AUTOSAR XML (schema 4-2-2)
# Copyright 2017 Mentor Graphics Corporation
# All rights reserved
# THIS WORK CONTAINS TRADE SECRET AND PROPRIETARY INFORMATION WHICH IS
# THE PROPERTY OF MENTOR GRAPHICS CORPORATION OR ITS LICENSORS AND IS
# SUBJECT TO LICENSE TERMS.
package /AUTOSAR/Services/Dcm
  swc implementation IMPL_Dcm: programming-language=C, sw-version=8.0.1, swc-bsw-mapping=SwcBswMapping_Dcm, vendor-id=31, behavior=IB_Dcm
    code-descriptors:
      code CODE_Dcm: artifact-descriptors=autosar-engineering-object={short-label=Dcm, category=SWSRC}
    resource consumption RC_Dcm
      memory section CODE: alignment=UNSPECIFIED, sw-addrmethod=CODE
  unit UnitNone
  5 x client server interface, all with is-service=true:
    CallbackDCMRequestServices
      operation StartProtocol: possible-error=[CallbackDCMRequestServices/E_OK, CallbackDCMRequestServices/E_NOT_OK, E_PROTOCOL_NOT_ALLOWED]
        arg ProtocolID: type=Dcm_ProtocolType, direction=IN
      operation StopProtocol: possible-error=[CallbackDCMRequestServices/E_OK, CallbackDCMRequestServices/E_NOT_OK]
        arg ProtocolID: type=Dcm_ProtocolType, direction=IN
      error E_OK: error-code=0
      error E_NOT_OK: error-code=1
      error E_PROTOCOL_NOT_ALLOWED: error-code=5
    ServiceRequestNotification
      operation Indication: possible-error=[ServiceRequestNotification/E_OK, ServiceRequestNotification/E_NOT_OK, E_REQUEST_NOT_ACCEPTED]
        6 x arg:
          SID: type=uint8, direction=IN
          RequestData: type=RequestDataArray, direction=IN
          DataSize: type=uint16, direction=IN
          ReqType: type=uint8, direction=IN
          SourceAddress: type=uint16, direction=IN
          ErrorCode: type=Dcm_NegativeResponseCodeType, direction=OUT
      operation Confirmation: possible-error=[ServiceRequestNotification/E_OK, ServiceRequestNotification/E_NOT_OK]
        4 x arg, all with direction=IN:
          SID: type=uint8
          ReqType: type=uint8
          SourceAddress: type=uint16
          ConfirmationStatus: type=Dcm_ConfirmationStatusType
      error E_OK: error-code=0
      error E_NOT_OK: error-code=1
      error E_REQUEST_NOT_ACCEPTED: error-code=8
    DCMServices
      4 x operation:
        GetActiveProtocol: possible-error=DCMServices/E_OK
          arg ActiveProtocol: type=Dcm_ProtocolType, direction=OUT
        GetSesCtrlType: possible-error=[DCMServices/E_OK, DCMServices/E_NOT_OK]
          arg SesCtrlType: type=Dcm_SesCtrlType, direction=OUT
        GetSecurityLevel: possible-error=[DCMServices/E_OK, DCMServices/E_NOT_OK]
          arg SecLevel: type=Dcm_SecLevelType, direction=OUT
        ResetToDefaultSession: possible-error=[DCMServices/E_OK, DCMServices/E_NOT_OK]
      error E_OK: error-code=0
      error E_NOT_OK: error-code=1
    ResponsePendingService
      operation GetResponsePendingStatus
        arg HasBeenSent: type=boolean, direction=OUT
    SecurityAccess_DcmDspSecurityRow
      operation GetSeed: possible-error=[SecurityAccess_DcmDspSecurityRow/E_OK, SecurityAccess_DcmDspSecurityRow/E_NOT_OK, DCM_E_PENDING]
        arg OpStatus: type=Dcm_OpStatusType, direction=IN
        arg Seed: type=SeedArrayType_DcmDspSecurityRow, direction=OUT
        arg ErrorCode: type=Dcm_NegativeResponseCodeType, direction=OUT
      operation CompareKey: possible-error=[SecurityAccess_DcmDspSecurityRow/E_OK, SecurityAccess_DcmDspSecurityRow/E_NOT_OK, DCM_E_PENDING, DCM_E_COMPARE_KEY_FAILED]
        arg Key: type=KeyArrayType_DcmDspSecurityRow, direction=IN
        arg OpStatus: type=Dcm_OpStatusType, direction=IN
        arg ErrorCode: type=Dcm_NegativeResponseCodeType, direction=OUT
      4 x error:
        E_OK: error-code=0
        E_NOT_OK: error-code=1
        DCM_E_PENDING: error-code=10
        DCM_E_COMPARE_KEY_FAILED: error-code=11
  5 x mode switch interface, all with is-service=true:
    DcmEcuReset
      mode group DcmEcuReset: type=DcmEcuReset
    DcmCommunicationControl
      mode group DcmCommunicationControl: type=DcmCommunicationControl
    DcmControlDTCSetting
      mode group DcmControlDTCSetting: type=DcmControlDTCSetting
    DcmModeRapidPowerShutDown
      mode group DcmModeRapidPowerShutDown: type=DcmModeRapidPowerShutDown
    DcmDiagnosticSessionControl
      mode group DcmDiagnosticSessionControl: type=DcmDiagnosticSessionControl
  impl type Dcm_ProtocolType: compu {0=DCM_OBD_ON_CAN, 1=DCM_OBD_ON_FLEXRAY, 2=DCM_OBD_ON_IP, 3=DCM_UDS_ON_CAN, 4=DCM_UDS_ON_FLEXRAY, 5=DCM_UDS_ON_IP, 6=DCM_ROE_ON_CAN, 7=DCM_ROE_ON_FLEXRAY, 8=DCM_ROE_ON_IP, 9=DCM_PERIODICTRANS_ON_CAN, 10=DCM_PERIODICTRANS_ON_FLEXRAY, 11=DCM_PERIODICTRANS_ON_IP, 12=DCM_NO_ACTIVE_PROTOCOL, 240..254=DCM_SUPPLIER_1..DCM_SUPPLIER_15}, implementation-data-type=uint8
  impl type Dcm_NegativeResponseCodeType: compu {16=DCM_E_GENERALREJECT, 17=DCM_E_SERVICENOTSUPPORTED, 18=DCM_E_SUBFUNCTIONNOTSUPPORTED, 19=DCM_E_INCORRECTMESSAGELENGTHORINVALIDFORMAT, 20=DCM_E_RESPONSETOOLONG, 33=DCM_E_BUSYREPEATREQUEST, 34=DCM_E_CONDITIONSNOTCORRECT, 36=DCM_E_REQUESTSEQUENCEERROR, 37=DCM_E_NORESPONSEFROMSUBNETCOMPONENT, 38=DCM_E_FAILUREPREVENTSEXECUTIONOFREQUESTEDACTION, 49=DCM_E_REQUESTOUTOFRANGE, 51=DCM_E_SECURITYACCESSDENIED, 53=DCM_E_INVALIDKEY, 54=DCM_E_EXCEEDNUMBEROFATTEMPTS, 55=DCM_E_REQUIREDTIMEDELAYNOTEXPIRED, 112=DCM_E_UPLOADDOWNLOADNOTACCEPTED, 113=DCM_E_TRANSFERDATASUSPENDED, 114=DCM_E_GENERALPROGRAMMINGFAILURE, 115=DCM_E_WRONGBLOCKSEQUENCECOUNTER, 126=DCM_E_SUBFUNCTIONNOTSUPPORTEDINACTIVESESSION, 127=DCM_E_SERVICENOTSUPPORTEDINACTIVESESSION, 129=DCM_E_RPMTOOHIGH, 130=DCM_E_RPMTOOLOW, 131=DCM_E_ENGINEISRUNNING, 132=DCM_E_ENGINEISNOTRUNNING, 133=DCM_E_ENGINERUNTIMETOOLOW, 134=DCM_E_TEMPERATURETOOHIGH, 135=DCM_E_TEMPERATURETOOLOW, 136=DCM_E_VEHICLESPEEDTOOHIGH, 137=DCM_E_VEHICLESPEEDTOOLOW, 138=DCM_E_THROTTLE_PEDALTOOHIGH, 139=DCM_E_THROTTLE_PEDALTOOLOW, 140=DCM_E_TRANSMISSIONRANGENOTINNEUTRAL, 141=DCM_E_TRANSMISSIONRANGENOTINGEAR, 143=DCM_E_BRAKESWITCH_NOTCLOSED, 144=DCM_E_SHIFTERLEVERNOTINPARK, 145=DCM_E_TORQUECONVERTERCLUTCHLOCKED, 146=DCM_E_VOLTAGETOOHIGH, 147=DCM_E_VOLTAGETOOLOW, 240..249=DCM_E_VMSCNC_0..DCM_E_VMSCNC_9, 250=DCM_E_VMSCNC_A, 251=DCM_E_VMSCNC_B, 252=DCM_E_VMSCNC_C, 253=DCM_E_VMSCNC_D, 254=DCM_E_VMSCNC_E}, implementation-data-type=uint8
  impl type Dcm_SecLevelType: compu {0=DCM_SEC_LEV_LOCKED, 1=DcmDspSecurityRow}, implementation-data-type=uint8
  impl type Dcm_SesCtrlType: compu {1=DCM_DEFAULT_SESSION, 2=DCM_PROGRAMMING_SESSION, 3=DCM_EXTENDED_DIAGNOSTIC_SESSION}, implementation-data-type=uint8
  impl type Dcm_OpStatusType: compu {0=DCM_INITIAL, 1=DCM_PENDING, 2=DCM_CANCEL, 3=DCM_FORCE_RCRRP_OK}, implementation-data-type=uint8
  impl type Dcm_ConfirmationStatusType: compu {0=DCM_RES_POS_OK, 1=DCM_RES_POS_NOT_OK, 2=DCM_RES_NEG_OK, 3=DCM_RES_NEG_NOT_OK}, implementation-data-type=uint8
  impl type Dcm_RoeStateType: compu {0=DCM_ROE_ACTIVE, 1=DCM_ROE_UNACTIVE}, implementation-data-type=uint8
  4 x impl type:
    KeyArrayType_DcmDspSecurityRow: category=ARRAY
      element ARRAYELEMENT: array-size=2, implementation-data-type=uint8
    RequestDataArray: category=ARRAY
      element ARRAYELEMENT: array-size=255, implementation-data-type=uint8
    SeedArrayType_DcmDspSecurityRow: category=ARRAY
      element ARRAYELEMENT: array-size=2, implementation-data-type=uint8
    Dcm_DidSupportedType: compu {0=DCM_DID_SUPPORTED, 1=DCM_DID_NOT_SUPPORTED}, implementation-data-type=uint8
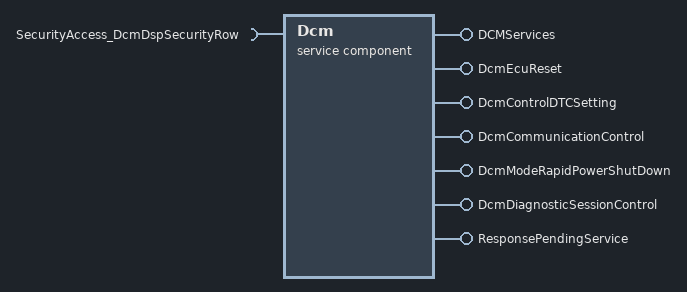
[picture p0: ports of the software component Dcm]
  service sw component type Dcm
    7 x provide port:
      DCMServices: provided-interface=DCMServices
        provided-com-specs:
          operation=GetActiveProtocol, queue-length=1
          operation=GetSesCtrlType, queue-length=1
          operation=GetSecurityLevel, queue-length=1
          operation=ResetToDefaultSession, queue-length=1
      DcmEcuReset: mode-switch-sender-com-spec{mode-group=DcmEcuReset, queue-length=2}, provided-interface=DcmEcuReset
      DcmControlDTCSetting: mode-switch-sender-com-spec{mode-group=DcmControlDTCSetting, queue-length=2}, provided-interface=DcmControlDTCSetting
      DcmCommunicationControl: mode-switch-sender-com-spec{mode-group=DcmCommunicationControl, queue-length=2}, provided-interface=DcmCommunicationControl
      DcmModeRapidPowerShutDown: mode-switch-sender-com-spec{mode-group=DcmModeRapidPowerShutDown, queue-length=2}, provided-interface=DcmModeRapidPowerShutDown
      DcmDiagnosticSessionControl: mode-switch-sender-com-spec{mode-group=DcmDiagnosticSessionControl, queue-length=2}, provided-interface=DcmDiagnosticSessionControl
      ResponsePendingService: server-com-spec{operation=GetResponsePendingStatus, queue-length=1}, provided-interface=ResponsePendingService
    require port SecurityAccess_DcmDspSecurityRow: required-interface=SecurityAccess_DcmDspSecurityRow
    behavior IB_Dcm: data-type-mapping=DcmModeMappingSet, handle-termination-and-restart=NO-SUPPORT, included-data-type-set=data-type=[Dcm_ProtocolType, Dcm_NegativeResponseCodeType, Dcm_SecLevelType, Dcm_SesCtrlType, Dcm_OpStatusType, Dcm_ConfirmationStatusType, Dcm_RoeStateType, Dcm_DidSupportedType]
      5 x operation invoked event:
        OI_GetActiveProtocol: start-on-event=RE_GetActiveProtocol, operation=DCMServices.GetActiveProtocol
        OI_GetSesCtrlType: start-on-event=RE_GetSesCtrlType, operation=DCMServices.GetSesCtrlType
        OI_GetSecurityLevel: start-on-event=RE_GetSecurityLevel, operation=DCMServices.GetSecurityLevel
        OI_ResetToDefaultSession: start-on-event=RE_ResetToDefaultSession, operation=DCMServices.ResetToDefaultSession
        OI_GetResponsePendingStatus: start-on-event=RE_GetResponsePendingStatus, operation=ResponsePendingService.GetResponsePendingStatus
      13 x runnable:
        RE_Dcm_ClearDiagnosticInformation: symbol=Dcm_SE_Dcm_ClearDiagnosticInformation
        RE_Dcm_DiagnosticSessionControl: symbol=Dcm_SE_Dcm_DiagnosticSessionControl
        RE_Dcm_MainFunction: symbol=Dcm_MainFunction
        RE_Dcm_ReadDTCInformation: symbol=Dcm_SE_Dcm_ReadDTCInformation
        RE_Dcm_ReadDataByIdentifier: symbol=Dcm_SE_Dcm_ReadDataByIdentifier
        RE_Dcm_SecurityAccess: symbol=Dcm_SE_Dcm_SecurityAccess
          sync call SSCP_SecurityAccess_DcmDspSecurityRow_CompareKey: operation=SecurityAccess_DcmDspSecurityRow.CompareKey, timeout=0.0
          sync call SSCP_SecurityAccess_DcmDspSecurityRow_GetSeed: operation=SecurityAccess_DcmDspSecurityRow.GetSeed, timeout=0.0
        RE_Dcm_TesterPresent: symbol=Dcm_SE_Dcm_TesterPresent
        RE_Dcm_WriteDataByIdentifier: symbol=Dcm_SE_Dcm_WriteDataByIdentifier
        RE_GetActiveProtocol: can-be-invoked-concurrently=true, symbol=Dcm_GetActiveProtocol
        RE_GetResponsePendingStatus: can-be-invoked-concurrently=true, symbol=Dcm_GetResponsePendingStatus
        RE_GetSecurityLevel: can-be-invoked-concurrently=true, symbol=Dcm_GetSecurityLevel
        RE_GetSesCtrlType: can-be-invoked-concurrently=true, symbol=Dcm_GetSesCtrlType
        RE_ResetToDefaultSession: can-be-invoked-concurrently=true, symbol=Dcm_ResetToDefaultSession
